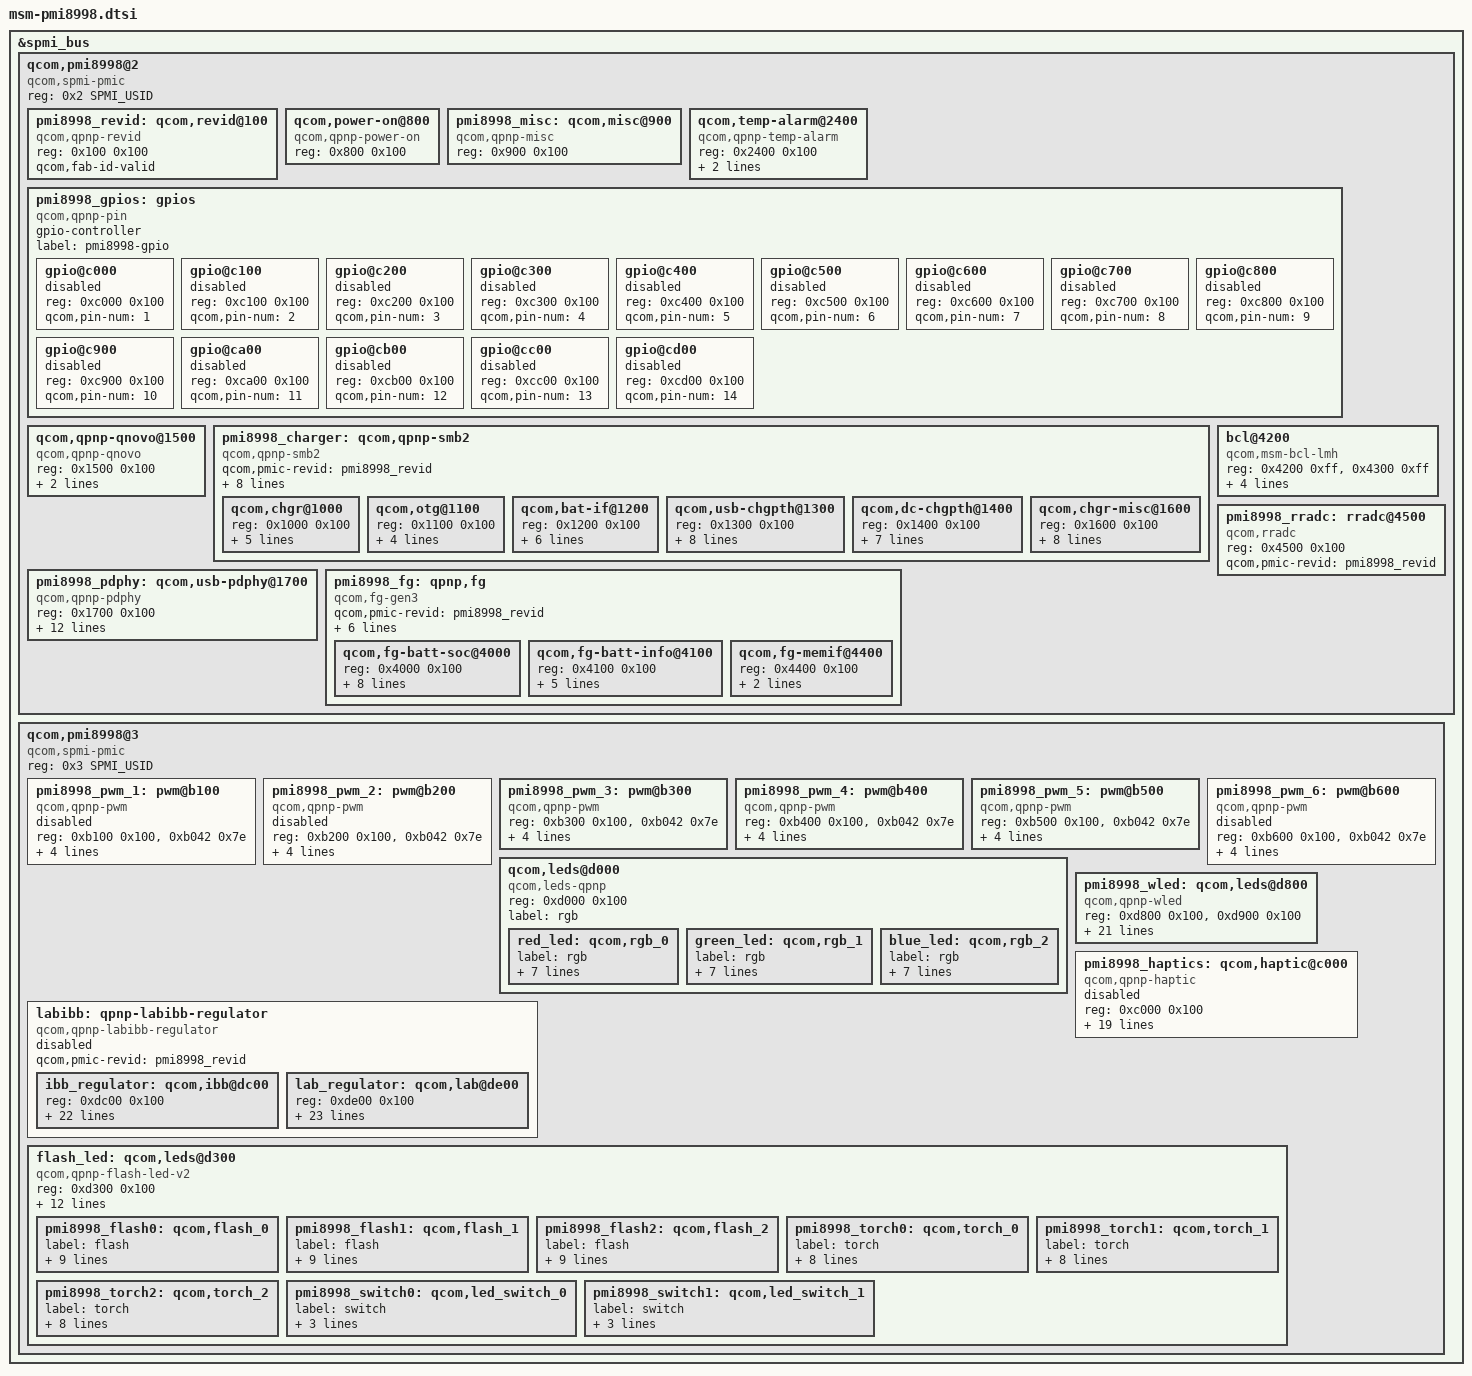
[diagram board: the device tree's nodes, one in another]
/* Copyright (c) 2016-2017, The Linux Foundation. All rights reserved.
 * Copyright (C) 2018 XiaoMi, Inc.
 *
 * This program is free software; you can redistribute it and/or modify
 * it under the terms of the GNU General Public License version 2 and
 * only version 2 as published by the Free Software Foundation.
 *
 * This program is distributed in the hope that it will be useful,
 * but WITHOUT ANY WARRANTY; without even the implied warranty of
 * MERCHANTABILITY or FITNESS FOR A PARTICULAR PURPOSE.  See the
 * GNU General Public License for more details.
 */

#include <dt-bindings/interrupt-controller/irq.h>
#include <dt-bindings/spmi/spmi.h>

&spmi_bus {
	qcom,pmi8998@2 {
		compatible = "qcom,spmi-pmic";
		reg = <0x2 SPMI_USID>;
		#address-cells = <2>;
		#size-cells = <0>;

		pmi8998_revid: qcom,revid@100 {
			compatible = "qcom,qpnp-revid";
			reg = <0x100 0x100>;
			qcom,fab-id-valid;
		};

		qcom,power-on@800 {
			compatible = "qcom,qpnp-power-on";
			reg = <0x800 0x100>;
		};

		pmi8998_misc: qcom,misc@900 {
			compatible = "qcom,qpnp-misc";
			reg = <0x900 0x100>;
		};

		qcom,temp-alarm@2400 {
			compatible = "qcom,qpnp-temp-alarm";
			reg = <0x2400 0x100>;
			interrupts = <0x2 0x24 0x0 IRQ_TYPE_EDGE_RISING>;
			label = "pmi8998_tz";
		};

		pmi8998_gpios: gpios {
			compatible = "qcom,qpnp-pin";
			gpio-controller;
			#gpio-cells = <2>;
			#address-cells = <1>;
			#size-cells = <1>;
			label = "pmi8998-gpio";

			gpio@c000 {
				reg = <0xc000 0x100>;
				qcom,pin-num = <1>;
				status = "disabled";
			};

			gpio@c100 {
				reg = <0xc100 0x100>;
				qcom,pin-num = <2>;
				status = "disabled";
			};

			gpio@c200 {
				reg = <0xc200 0x100>;
				qcom,pin-num = <3>;
				status = "disabled";
			};

			gpio@c300 {
				reg = <0xc300 0x100>;
				qcom,pin-num = <4>;
				status = "disabled";
			};

			gpio@c400 {
				reg = <0xc400 0x100>;
				qcom,pin-num = <5>;
				status = "disabled";
			};

			gpio@c500 {
				reg = <0xc500 0x100>;
				qcom,pin-num = <6>;
				status = "disabled";
			};

			gpio@c600 {
				reg = <0xc600 0x100>;
				qcom,pin-num = <7>;
				status = "disabled";
			};

			gpio@c700 {
				reg = <0xc700 0x100>;
				qcom,pin-num = <8>;
				status = "disabled";
			};

			gpio@c800 {
				reg = <0xc800 0x100>;
				qcom,pin-num = <9>;
				status = "disabled";
			};

			gpio@c900 {
				reg = <0xc900 0x100>;
				qcom,pin-num = <10>;
				status = "disabled";
			};

			gpio@ca00 {
				reg = <0xca00 0x100>;
				qcom,pin-num = <11>;
				status = "disabled";
			};

			gpio@cb00 {
				reg = <0xcb00 0x100>;
				qcom,pin-num = <12>;
				status = "disabled";
			};

			gpio@cc00 {
				reg = <0xcc00 0x100>;
				qcom,pin-num = <13>;
				status = "disabled";
			};

			gpio@cd00 {
				reg = <0xcd00 0x100>;
				qcom,pin-num = <14>;
				status = "disabled";
			};
		};

		qcom,qpnp-qnovo@1500 {
			compatible = "qcom,qpnp-qnovo";
			reg = <0x1500 0x100>;
			interrupts = <0x2 0x15 0x0 IRQ_TYPE_NONE>;
			interrupt-names = "ptrain-done";
			qcom,pmic-revid = <&pmi8998_revid>;
		};

		pmi8998_charger: qcom,qpnp-smb2 {
			compatible = "qcom,qpnp-smb2";
			#address-cells = <1>;
			#size-cells = <1>;

			qcom,pmic-revid = <&pmi8998_revid>;

			io-channels = <&pmi8998_rradc 8>,
				      <&pmi8998_rradc 10>,
				      <&pmi8998_rradc 3>,
				      <&pmi8998_rradc 4>;
			io-channel-names = "charger_temp",
					   "charger_temp_max",
					   "usbin_i",
					   "usbin_v";

			qcom,boost-threshold-ua = <100000>;
			qcom,wipower-max-uw = <5000000>;
			dpdm-supply = <&qusb_phy0>;

			qcom,thermal-mitigation
					= <3000000 1500000 1000000 500000>;

			qcom,chgr@1000 {
				reg = <0x1000 0x100>;
				interrupts =
					<0x2 0x10 0x0 IRQ_TYPE_EDGE_RISING>,
					<0x2 0x10 0x1 IRQ_TYPE_EDGE_RISING>,
					<0x2 0x10 0x2 IRQ_TYPE_EDGE_RISING>,
					<0x2 0x10 0x3 IRQ_TYPE_EDGE_RISING>,
					<0x2 0x10 0x4 IRQ_TYPE_EDGE_RISING>;

				interrupt-names = "chg-error",
						  "chg-state-change",
						  "step-chg-state-change",
						  "step-chg-soc-update-fail",
						  "step-chg-soc-update-request";
			};

			qcom,otg@1100 {
				reg = <0x1100 0x100>;
				interrupts = <0x2 0x11 0x0 IRQ_TYPE_EDGE_BOTH>,
					     <0x2 0x11 0x1 IRQ_TYPE_EDGE_BOTH>,
					     <0x2 0x11 0x2 IRQ_TYPE_EDGE_BOTH>,
					     <0x2 0x11 0x3 IRQ_TYPE_EDGE_BOTH>;

				interrupt-names = "otg-fail",
						  "otg-overcurrent",
						  "otg-oc-dis-sw-sts",
						  "testmode-change-detect";
			};

			qcom,bat-if@1200 {
				reg = <0x1200 0x100>;
				interrupts =
					<0x2 0x12 0x0 IRQ_TYPE_EDGE_RISING>,
					<0x2 0x12 0x1 IRQ_TYPE_EDGE_BOTH>,
					<0x2 0x12 0x2 IRQ_TYPE_EDGE_BOTH>,
					<0x2 0x12 0x3 IRQ_TYPE_EDGE_BOTH>,
					<0x2 0x12 0x4 IRQ_TYPE_EDGE_BOTH>,
					<0x2 0x12 0x5 IRQ_TYPE_EDGE_BOTH>;

				interrupt-names = "bat-temp",
						  "bat-ocp",
						  "bat-ov",
						  "bat-low",
						  "bat-therm-or-id-missing",
						  "bat-terminal-missing";
			};

			qcom,usb-chgpth@1300 {
				reg = <0x1300 0x100>;
				interrupts =
					<0x2 0x13 0x0 IRQ_TYPE_EDGE_BOTH>,
					<0x2 0x13 0x1 IRQ_TYPE_EDGE_BOTH>,
					<0x2 0x13 0x2 IRQ_TYPE_EDGE_BOTH>,
					<0x2 0x13 0x3 IRQ_TYPE_EDGE_BOTH>,
					<0x2 0x13 0x4 IRQ_TYPE_EDGE_BOTH>,
					<0x2 0x13 0x5 IRQ_TYPE_EDGE_RISING>,
					<0x2 0x13 0x6 IRQ_TYPE_EDGE_RISING>,
					<0x2 0x13 0x7 IRQ_TYPE_EDGE_RISING>;

				interrupt-names = "usbin-collapse",
						  "usbin-lt-3p6v",
						  "usbin-uv",
						  "usbin-ov",
						  "usbin-plugin",
						  "usbin-src-change",
						  "usbin-icl-change",
						  "type-c-change";
			};

			qcom,dc-chgpth@1400 {
				reg = <0x1400 0x100>;
				interrupts =
					<0x2 0x14 0x0 IRQ_TYPE_EDGE_BOTH>,
					<0x2 0x14 0x1 IRQ_TYPE_EDGE_BOTH>,
					<0x2 0x14 0x2 IRQ_TYPE_EDGE_BOTH>,
					<0x2 0x14 0x3 IRQ_TYPE_EDGE_BOTH>,
					<0x2 0x14 0x4 IRQ_TYPE_EDGE_BOTH>,
					<0x2 0x14 0x5 IRQ_TYPE_EDGE_BOTH>,
					<0x2 0x14 0x6 IRQ_TYPE_EDGE_RISING>;

				interrupt-names = "dcin-collapse",
						  "dcin-lt-3p6v",
						  "dcin-uv",
						  "dcin-ov",
						  "dcin-plugin",
						  "div2-en-dg",
						  "dcin-icl-change";
			};

			qcom,chgr-misc@1600 {
				reg = <0x1600 0x100>;
				interrupts =
					<0x2 0x16 0x0 IRQ_TYPE_EDGE_RISING>,
					<0x2 0x16 0x1 IRQ_TYPE_EDGE_RISING>,
					<0x2 0x16 0x2 IRQ_TYPE_EDGE_BOTH>,
					<0x2 0x16 0x3 IRQ_TYPE_EDGE_BOTH>,
					<0x2 0x16 0x4 IRQ_TYPE_EDGE_BOTH>,
					<0x2 0x16 0x5 IRQ_TYPE_EDGE_BOTH>,
					<0x2 0x16 0x6 IRQ_TYPE_EDGE_FALLING>,
					<0x2 0x16 0x7 IRQ_TYPE_EDGE_BOTH>;

				interrupt-names = "wdog-snarl",
						  "wdog-bark",
						  "aicl-fail",
						  "aicl-done",
						  "high-duty-cycle",
						  "input-current-limiting",
						  "temperature-change",
						  "switcher-power-ok";
			};
		};

		pmi8998_pdphy: qcom,usb-pdphy@1700 {
			compatible = "qcom,qpnp-pdphy";
			reg = <0x1700 0x100>;
			vdd-pdphy-supply = <&pm8998_l24>;
			vbus-supply = <&smb2_vbus>;
			vconn-supply = <&smb2_vconn>;
			interrupts = <0x2 0x17 0x0 IRQ_TYPE_EDGE_RISING>,
				     <0x2 0x17 0x1 IRQ_TYPE_EDGE_RISING>,
				     <0x2 0x17 0x2 IRQ_TYPE_EDGE_RISING>,
				     <0x2 0x17 0x3 IRQ_TYPE_EDGE_RISING>,
				     <0x2 0x17 0x4 IRQ_TYPE_EDGE_RISING>,
				     <0x2 0x17 0x5 IRQ_TYPE_EDGE_RISING>,
				     <0x2 0x17 0x6 IRQ_TYPE_EDGE_RISING>;

			interrupt-names = "sig-tx",
					  "sig-rx",
					  "msg-tx",
					  "msg-rx",
					  "msg-tx-failed",
					  "msg-tx-discarded",
					  "msg-rx-discarded";

			qcom,default-sink-caps = <5000 3000>, /* 5V @ 3A */
						 <9000 3000>, /* 9V @ 3A */
						 <12000 2250>; /* 12V @ 2.25A */
		};

		bcl@4200 {
			compatible = "qcom,msm-bcl-lmh";
			reg = <0x4200 0xff>,
				<0x4300 0xff>;
			reg-names = "fg_user_adc",
					"fg_lmh";
			interrupts = <0x2 0x42 0x0 IRQ_TYPE_NONE>,
					<0x2 0x42 0x2 IRQ_TYPE_NONE>;
			interrupt-names = "bcl-high-ibat-int",
					"bcl-low-vbat-int";
			qcom,vbat-polling-delay-ms = <100>;
			qcom,ibat-polling-delay-ms = <100>;
		};

		pmi8998_rradc: rradc@4500 {
			compatible = "qcom,rradc";
			reg = <0x4500 0x100>;
			#address-cells = <1>;
			#size-cells = <0>;
			#io-channel-cells = <1>;
			qcom,pmic-revid = <&pmi8998_revid>;
		};

		pmi8998_fg: qpnp,fg {
			compatible = "qcom,fg-gen3";
			#address-cells = <1>;
			#size-cells = <1>;
			qcom,pmic-revid = <&pmi8998_revid>;
			io-channels = <&pmi8998_rradc 0>;
			io-channel-names = "rradc_batt_id";
			qcom,rradc-base = <0x4500>;
			qcom,fg-esr-timer-awake = <96 96>;
			qcom,fg-esr-timer-asleep = <256 256>;
			qcom,fg-esr-timer-charging = <0 96>;
			qcom,cycle-counter-en;
			status = "okay";

			qcom,fg-batt-soc@4000 {
				status = "okay";
				reg = <0x4000 0x100>;
				interrupts = <0x2 0x40 0x0 IRQ_TYPE_EDGE_BOTH>,
					     <0x2 0x40 0x1 IRQ_TYPE_EDGE_BOTH>,
					     <0x2 0x40 0x2
							IRQ_TYPE_EDGE_RISING>,
					     <0x2 0x40 0x3
							IRQ_TYPE_EDGE_RISING>,
					     <0x2 0x40 0x4 IRQ_TYPE_EDGE_BOTH>,
					     <0x2 0x40 0x5
							IRQ_TYPE_EDGE_RISING>,
					     <0x2 0x40 0x6 IRQ_TYPE_EDGE_BOTH>,
					     <0x2 0x40 0x7 IRQ_TYPE_EDGE_BOTH>;
				interrupt-names = "soc-update",
						  "soc-ready",
						  "bsoc-delta",
						  "msoc-delta",
						  "msoc-low",
						  "msoc-empty",
						  "msoc-high",
						  "msoc-full";
			};

			qcom,fg-batt-info@4100 {
				status = "okay";
				reg = <0x4100 0x100>;
				interrupts = <0x2 0x41 0x0 IRQ_TYPE_EDGE_BOTH>,
					     <0x2 0x41 0x1 IRQ_TYPE_EDGE_BOTH>,
					     <0x2 0x41 0x2 IRQ_TYPE_EDGE_BOTH>,
					     <0x2 0x41 0x3 IRQ_TYPE_EDGE_BOTH>,
					     <0x2 0x41 0x6 IRQ_TYPE_EDGE_BOTH>;
				interrupt-names = "vbatt-pred-delta",
						  "vbatt-low",
						  "esr-delta",
						  "batt-missing",
						  "batt-temp-delta";
			};

			qcom,fg-memif@4400 {
				status = "okay";
				reg = <0x4400 0x100>;
				interrupts = <0x2 0x44 0x1 IRQ_TYPE_EDGE_BOTH>,
					     <0x2 0x44 0x2 IRQ_TYPE_EDGE_BOTH>;
				interrupt-names = "mem-xcp",
						  "dma-grant";
			};
		};
	};

	qcom,pmi8998@3 {
		compatible ="qcom,spmi-pmic";
		reg = <0x3 SPMI_USID>;
		#address-cells = <2>;
		#size-cells = <0>;

		pmi8998_pwm_1: pwm@b100 {
			compatible = "qcom,qpnp-pwm";
			reg = <0xb100 0x100>,
			      <0xb042 0x7e>;
			reg-names = "qpnp-lpg-channel-base",
					"qpnp-lpg-lut-base";
			qcom,lpg-lut-size = <0x7e>;
			qcom,channel-id = <1>;
			qcom,supported-sizes = <6>, <9>;
			qcom,ramp-index = <0>;
			#pwm-cells = <2>;
			status = "disabled";
		};

		pmi8998_pwm_2: pwm@b200 {
			compatible = "qcom,qpnp-pwm";
			reg = <0xb200 0x100>,
			      <0xb042 0x7e>;
			reg-names = "qpnp-lpg-channel-base",
					 "qpnp-lpg-lut-base";
			qcom,lpg-lut-size = <0x7e>;
			qcom,channel-id = <2>;
			qcom,supported-sizes = <6>, <9>;
			qcom,ramp-index = <1>;
			#pwm-cells = <2>;
			status = "disabled";
		};

		pmi8998_pwm_3: pwm@b300 {
			compatible = "qcom,qpnp-pwm";
			reg = <0xb300 0x100>,
			      <0xb042 0x7e>;
			reg-names = "qpnp-lpg-channel-base",
					 "qpnp-lpg-lut-base";
			qcom,lpg-lut-size = <0x7e>;
			qcom,channel-id = <3>;
			qcom,supported-sizes = <6>, <9>;
			qcom,ramp-index = <2>;
			#pwm-cells = <2>;
		};

		pmi8998_pwm_4: pwm@b400 {
			compatible = "qcom,qpnp-pwm";
			reg = <0xb400 0x100>,
			      <0xb042 0x7e>;
			reg-names = "qpnp-lpg-channel-base",
					 "qpnp-lpg-lut-base";
			qcom,lpg-lut-size = <0x7e>;
			qcom,channel-id = <4>;
			qcom,supported-sizes = <6>, <9>;
			qcom,ramp-index = <3>;
			#pwm-cells = <2>;
		};

		pmi8998_pwm_5: pwm@b500 {
			compatible = "qcom,qpnp-pwm";
			reg = <0xb500 0x100>,
			      <0xb042 0x7e>;
			reg-names = "qpnp-lpg-channel-base",
					 "qpnp-lpg-lut-base";
			qcom,lpg-lut-size = <0x7e>;
			qcom,channel-id = <5>;
			qcom,supported-sizes = <6>, <9>;
			qcom,ramp-index = <4>;
			#pwm-cells = <2>;
		};

		pmi8998_pwm_6: pwm@b600 {
			compatible = "qcom,qpnp-pwm";
			reg = <0xb600 0x100>,
			      <0xb042 0x7e>;
			reg-names = "qpnp-lpg-channel-base",
					 "qpnp-lpg-lut-base";
			qcom,lpg-lut-size = <0x7e>;
			qcom,channel-id = <6>;
			qcom,supported-sizes = <6>, <9>;
			qcom,ramp-index = <5>;
			#pwm-cells = <2>;
			status = "disabled";
		};

		qcom,leds@d000 {
			compatible = "qcom,leds-qpnp";
			reg = <0xd000 0x100>;
			label = "rgb";
			status = "okay";

			red_led: qcom,rgb_0 {
				label = "rgb";
				qcom,id = <3>;
				qcom,mode = "pwm";
				pwms = <&pmi8998_pwm_5 0 0>;
				qcom,pwm-us = <1000>;
				qcom,max-current = <12>;
				qcom,default-state = "off";
				linux,name = "red";
			};

			green_led: qcom,rgb_1 {
				label = "rgb";
				qcom,id = <4>;
				qcom,mode = "pwm";
				pwms = <&pmi8998_pwm_4 0 0>;
				qcom,pwm-us = <1000>;
				qcom,max-current = <12>;
				qcom,default-state = "off";
				linux,name = "green";
			};

			blue_led: qcom,rgb_2 {
				label = "rgb";
				qcom,id = <5>;
				qcom,mode = "pwm";
				pwms = <&pmi8998_pwm_3 0 0>;
				qcom,pwm-us = <1000>;
				qcom,max-current = <12>;
				qcom,default-state = "off";
				linux,name = "blue";
			};
		};

		labibb: qpnp-labibb-regulator {
			compatible = "qcom,qpnp-labibb-regulator";
			#address-cells = <1>;
			#size-cells = <1>;
			qcom,pmic-revid = <&pmi8998_revid>;
			status = "disabled";

			ibb_regulator: qcom,ibb@dc00 {
				reg = <0xdc00 0x100>;
				reg-names = "ibb_reg";
				regulator-name = "ibb_reg";

				regulator-min-microvolt = <4600000>;
				regulator-max-microvolt = <6000000>;

				interrupts = <0x3 0xdc 0x2
						IRQ_TYPE_EDGE_RISING>;
				interrupt-names = "ibb-sc-err";

				qcom,qpnp-ibb-min-voltage = <1400000>;
				qcom,qpnp-ibb-step-size = <100000>;
				qcom,qpnp-ibb-slew-rate = <2000000>;
				qcom,qpnp-ibb-use-default-voltage;
				qcom,qpnp-ibb-init-voltage = <5500000>;
				qcom,qpnp-ibb-init-amoled-voltage = <4000000>;
				qcom,qpnp-ibb-init-lcd-voltage = <5500000>;

				qcom,qpnp-ibb-soft-start = <1000>;

				qcom,qpnp-ibb-lab-pwrup-delay = <8000>;
				qcom,qpnp-ibb-lab-pwrdn-delay = <8000>;
				qcom,qpnp-ibb-en-discharge;

				qcom,qpnp-ibb-full-pull-down;
				qcom,qpnp-ibb-pull-down-enable;
				qcom,qpnp-ibb-switching-clock-frequency =
									<1480>;
				qcom,qpnp-ibb-limit-maximum-current = <1550>;
				qcom,qpnp-ibb-debounce-cycle = <16>;
				qcom,qpnp-ibb-limit-max-current-enable;
				qcom,qpnp-ibb-ps-enable;
			};

			lab_regulator: qcom,lab@de00 {
				reg = <0xde00 0x100>;
				reg-names = "lab";
				regulator-name = "lab_reg";

				regulator-min-microvolt = <4600000>;
				regulator-max-microvolt = <6000000>;

				interrupts = <0x3 0xde 0x0
						IRQ_TYPE_EDGE_RISING>,
					     <0x3 0xde 0x1
						IRQ_TYPE_EDGE_RISING>;
				interrupt-names = "lab-vreg-ok", "lab-sc-err";

				qcom,qpnp-lab-min-voltage = <4600000>;
				qcom,qpnp-lab-step-size = <100000>;
				qcom,qpnp-lab-slew-rate = <5000>;
				qcom,qpnp-lab-use-default-voltage;
				qcom,qpnp-lab-init-voltage = <5500000>;
				qcom,qpnp-lab-init-amoled-voltage = <4600000>;
				qcom,qpnp-lab-init-lcd-voltage = <5500000>;

				qcom,qpnp-lab-soft-start = <800>;

				qcom,qpnp-lab-full-pull-down;
				qcom,qpnp-lab-pull-down-enable;
				qcom,qpnp-lab-switching-clock-frequency =
									<1600>;
				qcom,qpnp-lab-limit-maximum-current = <1600>;
				qcom,qpnp-lab-limit-max-current-enable;
				qcom,qpnp-lab-ps-threshold = <20>;
				qcom,qpnp-lab-ps-enable;
				qcom,qpnp-lab-nfet-size = <100>;
				qcom,qpnp-lab-pfet-size = <100>;
				qcom,qpnp-lab-max-precharge-time = <500>;
			};
		};

		pmi8998_wled: qcom,leds@d800 {
			compatible = "qcom,qpnp-wled";
			reg = <0xd800 0x100>,
				<0xd900 0x100>;
			reg-names = "qpnp-wled-ctrl-base",
					"qpnp-wled-sink-base";
			interrupts = <0x3 0xd8 0x1 IRQ_TYPE_EDGE_RISING>,
					<0x3 0xd8 0x2 IRQ_TYPE_EDGE_RISING>;
			interrupt-names = "ovp-irq", "sc-irq";
			linux,name = "wled";
			linux,default-trigger = "bkl-trigger";
			qcom,fdbk-output = "auto";
			qcom,vref-uv = <127500>;
			qcom,switch-freq-khz = <600>;
			qcom,ovp-mv = <29600>;
			qcom,ilim-ma = <970>;
			qcom,boost-duty-ns = <26>;
			qcom,mod-freq-khz = <9600>;
			qcom,dim-mode = "hybrid";
			qcom,hyb-thres = <625>;
			qcom,sync-dly-us = <800>;
			qcom,fs-curr-ua = <25000>;
			qcom,cons-sync-write-delay-us = <1000>;
			qcom,led-strings-list = [00 01 02 03];
			qcom,en-ext-pfet-sc-pro;
			qcom,pmic-revid = <&pmi8998_revid>;
			qcom,loop-auto-gm-en;
			qcom,auto-calibration-enable;
			status = "okay";
		};

		pmi8998_haptics: qcom,haptic@c000 {
			status = "disabled";
			compatible = "qcom,qpnp-haptic";
			reg = <0xc000 0x100>;
			interrupts = <0x3 0xc0 0x0 IRQ_TYPE_EDGE_BOTH>,
				     <0x3 0xc0 0x1 IRQ_TYPE_EDGE_BOTH>;
			interrupt-names = "sc-irq", "play-irq";
			qcom,pmic-revid = <&pmi8998_revid>;
			qcom,pmic-misc = <&pmi8998_misc>;
			qcom,misc-clk-trim-error-reg = <0xf3>;
			qcom,actuator-type = "lra";
			qcom,play-mode = "direct";
			qcom,vmax-mv = <3200>;
			qcom,ilim-ma = <800>;
			qcom,wave-shape = "square";
			qcom,wave-play-rate-us = <6667>;
			qcom,int-pwm-freq-khz = <505>;
			qcom,sc-deb-cycles = <8>;
			qcom,en-brake;
			qcom,brake-pattern = [03 03 00 00];
			qcom,lra-high-z = "opt1";
			qcom,lra-auto-res-mode = "qwd";
			qcom,lra-res-cal-period = <4>;
			qcom,correct-lra-drive-freq;
		};

		flash_led: qcom,leds@d300 {
			compatible = "qcom,qpnp-flash-led-v2";
			status = "okay";
			reg = <0xd300 0x100>;
			label = "flash";
			interrupts = <0x3 0xd3 0x0 IRQ_TYPE_EDGE_RISING>,
					<0x3 0xd3 0x3 IRQ_TYPE_EDGE_RISING>,
					<0x3 0xd3 0x4 IRQ_TYPE_EDGE_RISING>;
			interrupt-names = "led-fault-irq",
					"all-ramp-down-done-irq",
					"all-ramp-up-done-irq";
			qcom,hdrm-auto-mode;
			qcom,short-circuit-det;
			qcom,open-circuit-det;
			qcom,vph-droop-det;
			qcom,thermal-derate-en;
			qcom,thermal-derate-current = <200 500 1000>;
			qcom,isc-delay = <192>;
			qcom,pmic-revid = <&pmi8998_revid>;

			pmi8998_flash0: qcom,flash_0 {
				label = "flash";
				qcom,led-name = "led:flash_0";
				qcom,max-current = <1500>;
				qcom,default-led-trigger = "flash0_trigger";
				qcom,id = <0>;
				qcom,current-ma = <1000>;
				qcom,duration-ms = <1280>;
				qcom,ires-ua = <13000>;
				qcom,hdrm-voltage-mv = <325>;
				qcom,hdrm-vol-hi-lo-win-mv = <100>;
			};

			pmi8998_flash1: qcom,flash_1 {
				label = "flash";
				qcom,led-name = "led:flash_1";
				qcom,max-current = <1500>;
				qcom,default-led-trigger = "flash1_trigger";
				qcom,id = <1>;
				qcom,current-ma = <1000>;
				qcom,duration-ms = <1280>;
				qcom,ires-ua = <13000>;
				qcom,hdrm-voltage-mv = <325>;
				qcom,hdrm-vol-hi-lo-win-mv = <100>;
			};

			pmi8998_flash2: qcom,flash_2 {
				label = "flash";
				qcom,led-name = "led:flash_2";
				qcom,max-current = <750>;
				qcom,default-led-trigger = "flash2_trigger";
				qcom,id = <2>;
				qcom,current-ma = <500>;
				qcom,duration-ms = <1280>;
				qcom,ires-ua = <12500>;
				qcom,hdrm-voltage-mv = <325>;
				qcom,hdrm-vol-hi-lo-win-mv = <100>;
			};

			pmi8998_torch0: qcom,torch_0 {
				label = "torch";
				qcom,led-name = "led:torch_0";
				qcom,max-current = <200>;
				qcom,default-led-trigger = "torch0_trigger";
				qcom,id = <0>;
				qcom,current-ma = <75>;
				qcom,ires-ua = <13000>;
				qcom,hdrm-voltage-mv = <325>;
				qcom,hdrm-vol-hi-lo-win-mv = <100>;
			};

			pmi8998_torch1: qcom,torch_1 {
				label = "torch";
				qcom,led-name = "led:torch_1";
				qcom,max-current = <200>;
				qcom,default-led-trigger = "torch1_trigger";
				qcom,id = <1>;
				qcom,current-ma = <75>;
				qcom,ires-ua = <13000>;
				qcom,hdrm-voltage-mv = <325>;
				qcom,hdrm-vol-hi-lo-win-mv = <100>;
			};

			pmi8998_torch2: qcom,torch_2 {
				label = "torch";
				qcom,led-name = "led:torch_2";
				qcom,max-current = <500>;
				qcom,default-led-trigger = "torch2_trigger";
				qcom,id = <2>;
				qcom,current-ma = <300>;
				qcom,ires-ua = <12500>;
				qcom,hdrm-voltage-mv = <325>;
				qcom,hdrm-vol-hi-lo-win-mv = <100>;
			};

			pmi8998_switch0: qcom,led_switch_0 {
				label = "switch";
				qcom,led-name = "led:switch_0";
				qcom,led-mask = <3>;
				qcom,default-led-trigger = "switch0_trigger";
			};

			pmi8998_switch1: qcom,led_switch_1 {
				label = "switch";
				qcom,led-name = "led:switch_1";
				qcom,led-mask = <4>;
				qcom,default-led-trigger = "switch1_trigger";
			};
		};
	};
};
